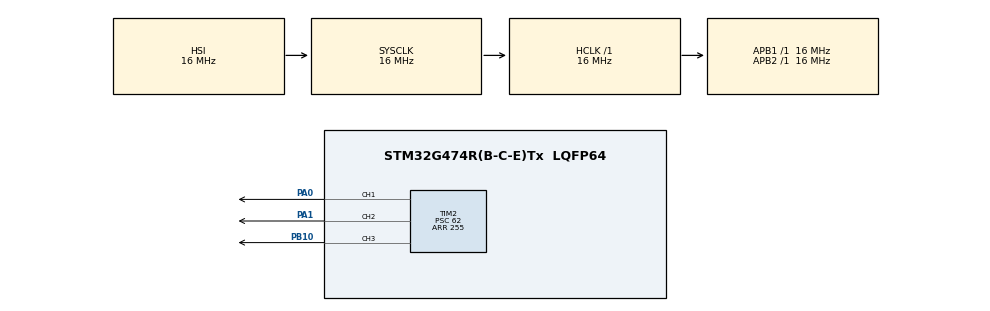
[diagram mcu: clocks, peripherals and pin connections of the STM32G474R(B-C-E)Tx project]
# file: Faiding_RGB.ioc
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Mcu.Family=STM32G4
Mcu.Name=STM32G474R(B-C-E)Tx
Mcu.Package=LQFP64
NVIC.PriorityGroup=NVIC_PRIORITYGROUP_4
NVIC.TIM6_DAC_IRQn=true\:0\:0\:false\:false\:true\:true\:true\:true
PA0.Signal=S_TIM2_CH1
PA1.Signal=S_TIM2_CH2
PB10.Signal=S_TIM2_CH3
ProjectManager.HeapSize=0x200
ProjectManager.StackSize=0x400
ProjectManager.TargetToolchain=STM32CubeIDE
RCC.AHBFreq_Value=16000000
RCC.APB1Freq_Value=16000000
RCC.APB1TimFreq_Value=16000000
RCC.APB2Freq_Value=16000000
RCC.APB2TimFreq_Value=16000000
RCC.CortexFreq_Value=16000000
RCC.EXTERNAL_CLOCK_VALUE=12288000
RCC.HCLKFreq_Value=16000000
RCC.HSE_VALUE=8000000
RCC.HSI48_VALUE=48000000
RCC.HSI_VALUE=16000000
RCC.LSE_VALUE=32768
RCC.SYSCLKFreq_VALUE=16000000
RCC.USBFreq_Value=64000000
RCC.VCOOutputFreq_Value=128000000
SH.S_TIM2_CH1.0=TIM2_CH1,PWM Generation1 CH1
SH.S_TIM2_CH2.0=TIM2_CH2,PWM Generation2 CH2
SH.S_TIM2_CH3.0=TIM2_CH3,PWM Generation3 CH3
TIM2.Channel-PWM\ Generation1\ CH1=TIM_CHANNEL_1
TIM2.Channel-PWM\ Generation2\ CH2=TIM_CHANNEL_2
TIM2.Channel-PWM\ Generation3\ CH3=TIM_CHANNEL_3
TIM2.PeriodNoDither=255
TIM2.Prescaler=62
TIM6.AutoReloadPreload=TIM_AUTORELOAD_PRELOAD_ENABLE
TIM6.PeriodNoDither=9
TIM6.Prescaler=15999
VP_SYS_VS_DBSignals.Mode=DisableDeadBatterySignals
VP_TIM6_VS_ClockSourceINT.Mode=Enable_Timer
board=custom

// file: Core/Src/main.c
/* USER CODE BEGIN Header */
/**
  ******************************************************************************
  * @file           : main.c
  * @brief          : Main program body
  ******************************************************************************
  * @attention
  *
  * Copyright (c) 2026 STMicroelectronics.
  * All rights reserved.
  *
  * This software is licensed under terms that can be found in the LICENSE file
  * in the root directory of this software component.
  * If no LICENSE file comes with this software, it is provided AS-IS.
  *
  ******************************************************************************
  */
/* USER CODE END Header */
#include "main.h"
#include "tim.h"
#include "gpio.h"

/* USER CODE BEGIN PV */

 uint8_t r = 255, g = 0, b = 0; // Colore di partenza: Rosso
 uint8_t fase = 0;              // Stato della macchina a stati
/* USER CODE END PV */

void SystemClock_Config(void);

int main(void)
{

  /* MCU Configuration--------------------------------------------------------*/

  /* Reset of all peripherals, Initializes the Flash interface and the Systick. */
  HAL_Init();

  /* Configure the system clock */
  SystemClock_Config();

  /* Initialize all configured peripherals */
  MX_GPIO_Init();
  MX_TIM2_Init();
  MX_TIM6_Init();
  /* USER CODE BEGIN 2 */
  // Avvia il PWM per i 3 canali del LED (Canali 1, 2 e 3)
  HAL_TIM_PWM_Start(&htim2, TIM_CHANNEL_1);
  HAL_TIM_PWM_Start(&htim2, TIM_CHANNEL_2);
  HAL_TIM_PWM_Start(&htim2, TIM_CHANNEL_3);

  // Avvia il Timer 6 in modalità Interrupt
  HAL_TIM_Base_Start_IT(&htim6);
  /* USER CODE END 2 */

  /* Infinite loop */
  while (1)
  {

  }
}

void SystemClock_Config(void)
{
  RCC_OscInitTypeDef RCC_OscInitStruct = {0};
  RCC_ClkInitTypeDef RCC_ClkInitStruct = {0};

  /** Configure the main internal regulator output voltage
  */
  HAL_PWREx_ControlVoltageScaling(PWR_REGULATOR_VOLTAGE_SCALE1);

  /** Initializes the RCC Oscillators according to the specified parameters
  * in the RCC_OscInitTypeDef structure.
  */
  RCC_OscInitStruct.OscillatorType = RCC_OSCILLATORTYPE_HSI;
  RCC_OscInitStruct.HSIState = RCC_HSI_ON;
  RCC_OscInitStruct.HSICalibrationValue = RCC_HSICALIBRATION_DEFAULT;
  RCC_OscInitStruct.PLL.PLLState = RCC_PLL_NONE;
  if (HAL_RCC_OscConfig(&RCC_OscInitStruct) != HAL_OK)
  {
    Error_Handler();
  }

  /** Initializes the CPU, AHB and APB buses clocks
  */
  RCC_ClkInitStruct.ClockType = RCC_CLOCKTYPE_HCLK|RCC_CLOCKTYPE_SYSCLK
                              |RCC_CLOCKTYPE_PCLK1|RCC_CLOCKTYPE_PCLK2;
  RCC_ClkInitStruct.SYSCLKSource = RCC_SYSCLKSOURCE_HSI;
  RCC_ClkInitStruct.AHBCLKDivider = RCC_SYSCLK_DIV1;
  RCC_ClkInitStruct.APB1CLKDivider = RCC_HCLK_DIV1;
  RCC_ClkInitStruct.APB2CLKDivider = RCC_HCLK_DIV1;

  if (HAL_RCC_ClockConfig(&RCC_ClkInitStruct, FLASH_LATENCY_0) != HAL_OK)
  {
    Error_Handler();
  }
}

/* USER CODE BEGIN 4 */
void HAL_TIM_PeriodElapsedCallback(TIM_HandleTypeDef *htim)
{
  if (htim->Instance == TIM6)
  {
    switch (fase) {
      case 0: // Da rosso a giallo (Aumenta verde)
        if (++g == 255) fase = 1;
        break;
      case 1: // Da giallo a verde (Diminuisce rosso)
        if (--r == 0)   fase = 2;
        break;
      case 2: // Da verde a ciano (Aumenta blu)
        if (++b == 255) fase = 3;
        break;
      case 3: // Da ciano a blu (Diminuisce verde)
        if (--g == 0)   fase = 4;
        break;
      case 4: // Da blu a Magenta (Aumenta rosso)
        if (++r == 255) fase = 5;
        break;
      case 5: // Da magenta a rosso (Diminuisce blu)
        if (--b == 0)   fase = 0;
        break;
    }

    // Applica i valori ai registri del Timer 2 (PWM)
    __HAL_TIM_SET_COMPARE(&htim2, TIM_CHANNEL_1, r);
    __HAL_TIM_SET_COMPARE(&htim2, TIM_CHANNEL_2, g);
    __HAL_TIM_SET_COMPARE(&htim2, TIM_CHANNEL_3, b);
  }
}
/* USER CODE END 4 */

void Error_Handler(void)
{
  __disable_irq();
  while (1)
  {
  }
}
